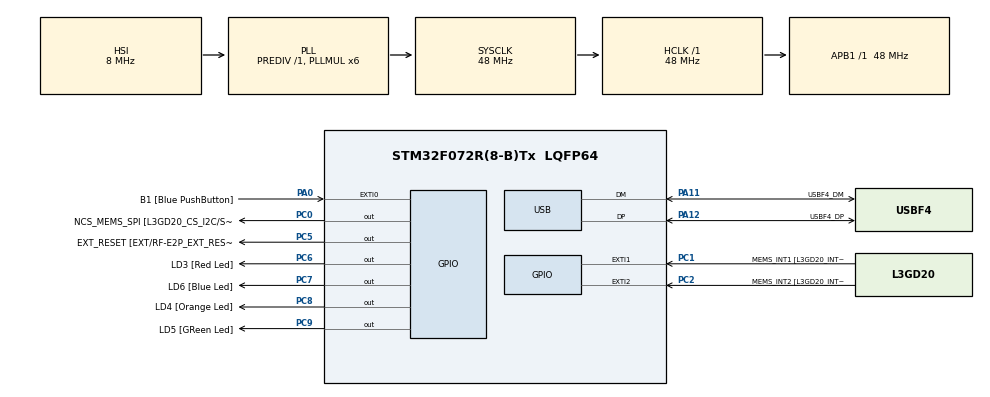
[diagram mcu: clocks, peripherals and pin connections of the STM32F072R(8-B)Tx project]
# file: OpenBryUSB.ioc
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Mcu.Family=STM32F0
Mcu.Name=STM32F072R(8-B)Tx
Mcu.Package=LQFP64
NVIC.USB_IRQn=true\:0\:0\:false\:false\:true
PA0.GPIO_Label=B1 [Blue PushButton]
PA0.GPIO_ModeDefaultEXTI=GPIO_MODE_EVT_RISING
PA0.Signal=GPXTI0
PA11.GPIO_Label=USBF4_DM
PA11.Mode=Device
PA11.Signal=USB_DM
PA12.GPIO_Label=USBF4_DP
PA12.Mode=Device
PA12.Signal=USB_DP
PA13.GPIO_Label=SWDIO
PA13.Signal=SYS_SWDIO
PA14.GPIO_Label=SWCLK
PA14.Signal=SYS_SWCLK
PA2.Signal=TSC_G1_IO3
PA3.Signal=TSC_G1_IO4
PA6.Signal=TSC_G2_IO3
PA7.Signal=TSC_G2_IO4
PB0.Signal=TSC_G3_IO2
PB1.Signal=TSC_G3_IO3
PB10.GPIO_Label=I2C2_SCL[EXT/RF-E2P_SCL]
PB10.Signal=I2C2_SCL
PB11.GPIO_Label=I2C2_SDA[EXT/RF-E2P_SDA]
PB11.Signal=I2C2_SDA
PB13.GPIO_Label=SPI2_SCK [L3GD20_SCL/SPC]
PB13.Signal=SPI2_SCK
PB14.GPIO_Label=SPI2_MISO [L3GD20_SDO]
PB14.Signal=SPI2_MISO
PB15.GPIO_Label=SPI2_MOSI [L3GD20_SDA/SDI]
PB15.Signal=SPI2_MOSI
PC0.GPIO_Label=NCS_MEMS_SPI [L3GD20_CS_I2C/SPI]
PC0.Signal=GPIO_Output
PC1.GPIO_Label=MEMS_INT1 [L3GD20_INT1]
PC1.GPIO_ModeDefaultEXTI=GPIO_MODE_EVT_RISING
PC1.Signal=GPXTI1
PC2.GPIO_Label=MEMS_INT2 [L3GD20_INT2]
PC2.GPIO_ModeDefaultEXTI=GPIO_MODE_EVT_RISING
PC2.Signal=GPXTI2
PC5.GPIO_Label=EXT_RESET [EXT/RF-E2P_EXT_RESET]
PC5.Signal=GPIO_Output
PC6.GPIO_Label=LD3 [Red Led]
PC6.Signal=GPIO_Output
PC7.GPIO_Label=LD6 [Blue Led]
PC7.Signal=GPIO_Output
PC8.GPIO_Label=LD4 [Orange Led]
PC8.Signal=GPIO_Output
PC9.GPIO_Label=LD5 [GReen Led]
PC9.Signal=GPIO_Output
ProjectManager.HeapSize=0x200
ProjectManager.StackSize=0x400
ProjectManager.TargetToolchain=SW4STM32
RCC.AHBFreq_Value=48000000
RCC.APB1Freq_Value=48000000
RCC.APB1TimFreq_Value=48000000
RCC.CECEnable=false
RCC.ClockTypeHCLK=RCC_CLOCKTYPE_HCLK
RCC.ClockTypePCLK1=RCC_CLOCKTYPE_PCLK1
RCC.DATA_CACHE_ENABLE=0
RCC.EnableHSE=false
RCC.EnableHSERTCDevisor=false
RCC.EnableLSE=false
RCC.EnableLSERTC=false
RCC.EnableMCOMultDivisor=false
RCC.HCLKFreq_Value=48000000
RCC.HSEState=RCC_HSE_OFF
RCC.HSI14State=RCC_HSI14_OFF
RCC.HSI48State=RCC_HSI48_ON
RCC.HSIState=RCC_HSI_ON
RCC.I2C1Enable=false
RCC.INSTRUCTION_CACHE_ENABLE=0
RCC.IWDGEnable=false
RCC.LSIState=RCC_LSI_OFF
RCC.MCOEnable=false
RCC.OscillatorTypeHSI=RCC_OSCILLATORTYPE_HSI
RCC.OscillatorTypeHSI48=RCC_OSCILLATORTYPE_HSI48
RCC.PLLMUL=RCC_PLL_MUL6
RCC.PLLSource=RCC_PLLSOURCE_HSI
RCC.PLLState=RCC_PLL_ON
RCC.RTCEnable=false
RCC.SYSCLKFreq_VALUE=48000000
RCC.SYSCLKSource=RCC_SYSCLKSOURCE_PLLCLK
RCC.USART1Enable=false
RCC.USART2Enable=false
RCC.USBEnable=true
USB_DEVICE.CLASS_NAME_FS=CDC
USB_DEVICE.USBD_HandleTypeDef_FS=hUsbDevice_USB_FS
USB_DEVICE.VirtualMode=Cdc
USB_DEVICE.VirtualModeFS=Cdc_FS
VP_USB_DEVICE_VS_USB_DEVICE_CDC_FS.Mode=CDC_FS
board=STM32F072B-DISCO

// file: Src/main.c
/**
  ******************************************************************************
  * File Name          : main.c
  * Description        : Main program body
  ******************************************************************************
  *
  * Copyright (c) 2017 STMicroelectronics International N.V.
  * All rights reserved.
  *
  * Redistribution and use in source and binary forms, with or without
  * modification, are permitted, provided that the following conditions are met:
  *
  * 1. Redistribution of source code must retain the above copyright notice,
  *    this list of conditions and the following disclaimer.
  * 2. Redistributions in binary form must reproduce the above copyright notice,
  *    this list of conditions and the following disclaimer in the documentation
  *    and/or other materials provided with the distribution.
  * 3. Neither the name of STMicroelectronics nor the names of other
  *    contributors to this software may be used to endorse or promote products
  *    derived from this software without specific written permission.
  * 4. This software, including modifications and/or derivative works of this
  *    software, must execute solely and exclusively on microcontroller or
  *    microprocessor devices manufactured by or for STMicroelectronics.
  * 5. Redistribution and use of this software other than as permitted under
  *    this license is void and will automatically terminate your rights under
  *    this license.
  *
  * THIS SOFTWARE IS PROVIDED BY STMICROELECTRONICS AND CONTRIBUTORS "AS IS"
  * AND ANY EXPRESS, IMPLIED OR STATUTORY WARRANTIES, INCLUDING, BUT NOT
  * LIMITED TO, THE IMPLIED WARRANTIES OF MERCHANTABILITY, FITNESS FOR A
  * PARTICULAR PURPOSE AND NON-INFRINGEMENT OF THIRD PARTY INTELLECTUAL PROPERTY
  * RIGHTS ARE DISCLAIMED TO THE FULLEST EXTENT PERMITTED BY LAW. IN NO EVENT
  * SHALL STMICROELECTRONICS OR CONTRIBUTORS BE LIABLE FOR ANY DIRECT, INDIRECT,
  * INCIDENTAL, SPECIAL, EXEMPLARY, OR CONSEQUENTIAL DAMAGES (INCLUDING, BUT NOT
  * LIMITED TO, PROCUREMENT OF SUBSTITUTE GOODS OR SERVICES; LOSS OF USE, DATA,
  * OR PROFITS; OR BUSINESS INTERRUPTION) HOWEVER CAUSED AND ON ANY THEORY OF
  * LIABILITY, WHETHER IN CONTRACT, STRICT LIABILITY, OR TORT (INCLUDING
  * NEGLIGENCE OR OTHERWISE) ARISING IN ANY WAY OUT OF THE USE OF THIS SOFTWARE,
  * EVEN IF ADVISED OF THE POSSIBILITY OF SUCH DAMAGE.
  *
  ******************************************************************************
  */
#include "main.h"
#include "stm32f0xx_hal.h"
#include "usb_device.h"
#include "gpio.h"

/* USER CODE BEGIN Includes */
#include "inttypes.h"
#include "usbd_cdc_if.h"
/* USER CODE END Includes */

/* USER CODE BEGIN PV */
/* Private variables ---------------------------------------------------------*/
uint8_t DataToSend[512]; // Tablica zawierajaca dane do wyslania
uint32_t MessageCounter = 0; // Licznik wyslanych wiadomosci
uint32_t MessageLength = 0; // Zawiera dlugosc wysylanej wiadomosci
/* USER CODE END PV */

void SystemClock_Config(void);
void Error_Handler(void);

/* USER CODE BEGIN PFP */
/* Private function prototypes -----------------------------------------------*/

/* USER CODE END PFP */

int main(void)
{

  /* USER CODE BEGIN 1 */
	char *buf;
  /* USER CODE END 1 */

  /* MCU Configuration----------------------------------------------------------*/

  /* Reset of all peripherals, Initializes the Flash interface and the Systick. */
  HAL_Init();

  /* Configure the system clock */
  SystemClock_Config();

  /* Initialize all configured peripherals */
  MX_GPIO_Init();
  MX_USB_DEVICE_Init();

  /* Infinite loop */
  while (1)
  {

	  buf = cdc_get_line();

	  if(buf != NULL){
		  cdc_chomp_line();
		  MessageLength = sprintf(DataToSend, "%s\n",  buf);
		  CDC_Transmit_FS(DataToSend, MessageLength);

	  }

  }

}

/** System Clock Configuration
*/
void SystemClock_Config(void)
{

  RCC_OscInitTypeDef RCC_OscInitStruct;
  RCC_ClkInitTypeDef RCC_ClkInitStruct;
  RCC_PeriphCLKInitTypeDef PeriphClkInit;

    /**Initializes the CPU, AHB and APB busses clocks
    */
  RCC_OscInitStruct.OscillatorType = RCC_OSCILLATORTYPE_HSI|RCC_OSCILLATORTYPE_HSI48;
  RCC_OscInitStruct.HSIState = RCC_HSI_ON;
  RCC_OscInitStruct.HSI48State = RCC_HSI48_ON;
  RCC_OscInitStruct.HSICalibrationValue = 16;
  RCC_OscInitStruct.PLL.PLLState = RCC_PLL_ON;
  RCC_OscInitStruct.PLL.PLLSource = RCC_PLLSOURCE_HSI;
  RCC_OscInitStruct.PLL.PLLMUL = RCC_PLL_MUL6;
  RCC_OscInitStruct.PLL.PREDIV = RCC_PREDIV_DIV1;
  if (HAL_RCC_OscConfig(&RCC_OscInitStruct) != HAL_OK)
  {
    Error_Handler();
  }

    /**Initializes the CPU, AHB and APB busses clocks
    */
  RCC_ClkInitStruct.ClockType = RCC_CLOCKTYPE_HCLK|RCC_CLOCKTYPE_SYSCLK
                              |RCC_CLOCKTYPE_PCLK1;
  RCC_ClkInitStruct.SYSCLKSource = RCC_SYSCLKSOURCE_PLLCLK;
  RCC_ClkInitStruct.AHBCLKDivider = RCC_SYSCLK_DIV1;
  RCC_ClkInitStruct.APB1CLKDivider = RCC_HCLK_DIV1;

  if (HAL_RCC_ClockConfig(&RCC_ClkInitStruct, FLASH_LATENCY_1) != HAL_OK)
  {
    Error_Handler();
  }

  PeriphClkInit.PeriphClockSelection = RCC_PERIPHCLK_USB;
  PeriphClkInit.UsbClockSelection = RCC_USBCLKSOURCE_HSI48;

  if (HAL_RCCEx_PeriphCLKConfig(&PeriphClkInit) != HAL_OK)
  {
    Error_Handler();
  }

    /**Configure the Systick interrupt time
    */
  HAL_SYSTICK_Config(HAL_RCC_GetHCLKFreq()/1000);

    /**Configure the Systick
    */
  HAL_SYSTICK_CLKSourceConfig(SYSTICK_CLKSOURCE_HCLK);

  /* SysTick_IRQn interrupt configuration */
  HAL_NVIC_SetPriority(SysTick_IRQn, 0, 0);
}

void Error_Handler(void)
{
  while(1)
  {
  }
}

/************************ (C) COPYRIGHT STMicroelectronics *****END OF FILE****/
